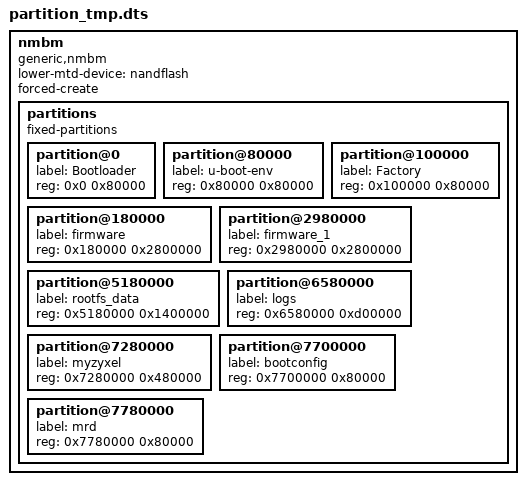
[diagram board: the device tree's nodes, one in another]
	nmbm {
		compatible = "generic,nmbm";
		#address-cells = <1>;
		#size-cells = <1>;
		lower-mtd-device = <&nandflash>;
		forced-create;
		partitions {
			compatible = "fixed-partitions";
			#address-cells = <1>;
			#size-cells = <1>;

			partition@0 {
				label = "Bootloader";
				reg = <0x0 0x80000>;
			};

			partition@80000 {
				label = "u-boot-env";
				reg = <0x80000 0x80000>;
			};

			partition@100000 {
				label = "Factory";
				reg = <0x100000 0x80000>;
			};

			partition@180000 {
				label = "firmware";
				reg = <0x180000 0x2800000>;
			};

			partition@2980000 {
				label = "firmware_1";
				reg = <0x2980000 0x2800000>;
			};

			partition@5180000 {
				label = "rootfs_data";
				reg = <0x5180000 0x1400000>;
			};

			partition@6580000 {
				label = "logs";
				reg = <0x6580000 0xd00000>;
			};

			partition@7280000 {
				label = "myzyxel";
				reg = <0x7280000 0x480000>;
			};

			partition@7700000 {
				label = "bootconfig";
				reg = <0x7700000 0x80000>;
			};

			partition@7780000 {
				label = "mrd";
				reg = <0x7780000 0x80000>;
			};
		};
	};
